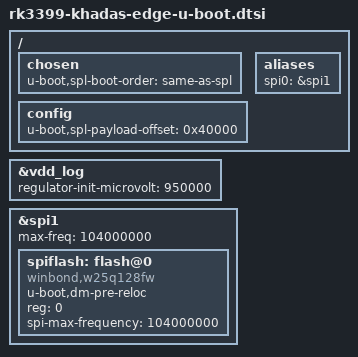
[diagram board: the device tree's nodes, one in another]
// SPDX-License-Identifier: GPL-2.0+
/*
 * Copyright (C) 2019 Nick Xie <nick@khadas.com>
 */

#include "rk3399-u-boot.dtsi"
#include "rk3399-sdram-lpddr4-100.dtsi"

/ {
	chosen {
		u-boot,spl-boot-order = "same-as-spl", &spiflash, &sdhci, &sdmmc;
	};

       config {
               u-boot,spl-payload-offset = <0x40000>; /* @ 256KB */
               //u-boot,mmc-env-offset = <0x4000>;      /* @  16KB */
               //u-boot,efi-partition-entries-offset = <0x200000>; /* 2MB */
               //u-boot,boot-led = "module_led";
               //sysreset-gpio = <&gpio1 RK_PA6 GPIO_ACTIVE_HIGH>;
       };
	
	aliases {
	    spi0 = &spi1;
	};
	
};

&vdd_log {
	regulator-init-microvolt = <950000>;
};

&spi1 {
    max-freq = <104000000>;
    status = "okay";

    spiflash: flash@0 {
	u-boot,dm-pre-reloc;
	compatible = "winbond,w25q128fw", "jedec,spi-nor";
	reg = <0>;
	spi-max-frequency = <104000000>;
    };
};
